# PIC18LF252 register map
Vendor: Microchip
Architecture 18xxxx. Special function registers and configuration words.
Registers are 8-bit, read-write, no defined reset value unless marked. A register's access mark holds for its fields unless they carry their own. Addresses are absolute, and some are shared; only a register's first bit layout is shown; lines under a group give offsets from that group; [hi:lo] are bit positions; {n}, {i} and the like mark numbered series; 'fields as' and 'values as' point back to an identical list; <NAME> marks a mode.

## Further device data
pins=1: MCLR/VPP; 2: RA0/AN0; 3: RA1/AN1; 4: RA2/AN2/VREF-; 5: RA3/AN3/VREF+; 6: RA4/T0CKI; 7: RA5/AN4/SS/LVDIN; 8: VSS; 9: OSC1/CLKI; 10: OSC2/CLKO/RA6; 11: RC0/T1OSO/T1CKI; 12: RC1/T1OSI/CCP2; 13: RC2/CCP1; 14: RC3/SCK/SCL; 15: RC4/SDI/SDA; 16: RC5/SDO; 17: RC6/TX/CK; 18: RC7/RX/DT; 19: VSS; 20: VDD; 21: RB0/INT0; 22: RB1/INT1; 23: RB2/INT2; 24: RB3/CCP2; 25: RB4; 26: RB5/PGM; 27: RB6/PGC; 28: RB7/PGD

## SFR
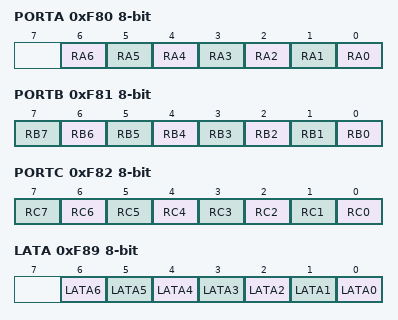
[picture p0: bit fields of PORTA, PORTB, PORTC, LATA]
0xF80 PORTA — (power-on value -x0x0000)
  [n] RA{n} (n=0..6)
0xF81 PORTB — (power-on value xxxxxxxx)
  [n] RB{n} (n=0..7)
0xF82 PORTC — (power-on value xxxxxxxx)
  [n] RC{n} (n=0..7)
0xF89 LATA — (power-on value -xxxxxxx)
  [n] LATA{n} (n=0..6)
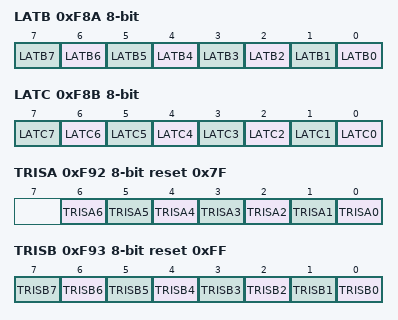
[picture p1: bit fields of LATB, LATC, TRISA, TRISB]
0xF8A LATB — (power-on value xxxxxxxx)
  [n] LATB{n} (n=0..7)
0xF8B LATC — (power-on value xxxxxxxx)
  [n] LATC{n} (n=0..7)
0xF92 TRISA reset 0x7F
  [n] TRISA{n} (n=0..6)
0xF93 TRISB reset 0xFF
  [n] TRISB{n} (n=0..7)
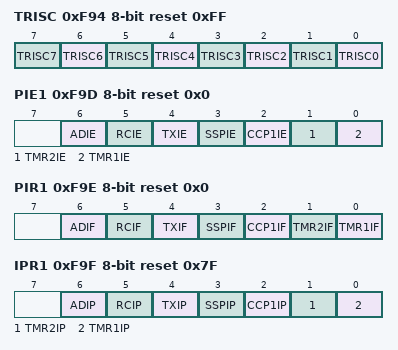
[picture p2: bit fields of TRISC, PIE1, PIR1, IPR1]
0xF94 TRISC reset 0xFF
  [n] TRISC{n} (n=0..7)
0xF9D PIE1 reset 0x0
  [6] ADIE, [5] RCIE, [4] TXIE, [3] SSPIE, [2] CCP1IE, [1] TMR2IE, [0] TMR1IE
0xF9E PIR1 reset 0x0
  [6] ADIF, [5] RCIF ro, [4] TXIF ro, [3] SSPIF, [2] CCP1IF, [1] TMR2IF, [0] TMR1IF
0xF9F IPR1 reset 0x7F
  [6] ADIP, [5] RCIP, [4] TXIP, [3] SSPIP, [2] CCP1IP, [1] TMR2IP, [0] TMR1IP
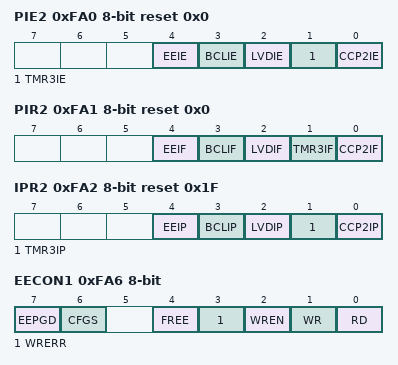
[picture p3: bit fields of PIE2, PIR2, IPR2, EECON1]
0xFA0 PIE2 reset 0x0
  [4] EEIE, [3] BCLIE, [2] LVDIE, [1] TMR3IE, [0] CCP2IE
0xFA1 PIR2 reset 0x0
  [4] EEIF, [3] BCLIF, [2] LVDIF, [1] TMR3IF, [0] CCP2IF
0xFA2 IPR2 reset 0x1F
  [4] EEIP, [3] BCLIP, [2] LVDIP, [1] TMR3IP, [0] CCP2IP
0xFA6 EECON1 — (power-on value xx-0x000)
  [7] EEPGD
  [6] CFGS
  [4] FREE
  [3] WRERR
  [2] WREN
  [1] WR — (can only be set)
  [0] RD — (can only be set)
0xFA7 EECON2 wo
0xFA8 EEDATA reset 0x0
0xFA9 EEADR reset 0x0
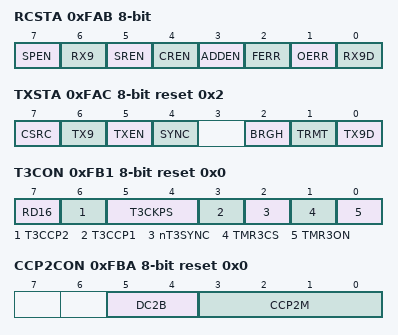
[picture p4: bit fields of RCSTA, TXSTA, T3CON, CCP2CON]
0xFAB RCSTA — (power-on value 0000000x)
  [7] SPEN, [6] RX9, [5] SREN, [4] CREN, [3] ADDEN, [2] FERR ro, [1] OERR ro, [0] RX9D ro
0xFAC TXSTA reset 0x2
  [7] CSRC, [6] TX9, [5] TXEN, [4] SYNC, [2] BRGH, [1] TRMT ro, [0] TX9D
0xFAD TXREG wo reset 0x0
0xFAE RCREG ro reset 0x0
0xFAF SPBRG reset 0x0
0xFB1 T3CON reset 0x0
  [7] RD16, [6] T3CCP2, [5:4] T3CKPS, [3] T3CCP1, [2] nT3SYNC, [1] TMR3CS, [0] TMR3ON
0xFB2 TMR3L — (power-on value xxxxxxxx)
0xFB3 TMR3H — (power-on value xxxxxxxx)
0xFBA CCP2CON reset 0x0
  [5:4] DC2B, [3:0] CCP2M
0xFBB CCPR2L — (power-on value xxxxxxxx)
0xFBC CCPR2H — (power-on value xxxxxxxx)
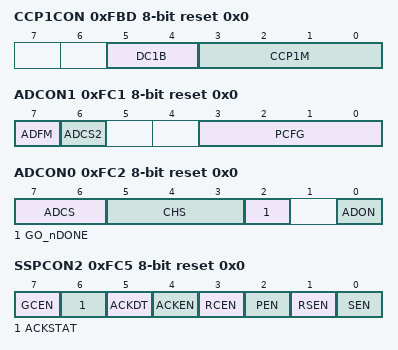
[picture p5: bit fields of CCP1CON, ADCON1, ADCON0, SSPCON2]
0xFBD CCP1CON reset 0x0
  [5:4] DC1B, [3:0] CCP1M
0xFBE CCPR1L — (power-on value xxxxxxxx)
0xFBF CCPR1H — (power-on value xxxxxxxx)
0xFC1 ADCON1 reset 0x0
  [7] ADFM, [6] ADCS2, [3:0] PCFG
0xFC2 ADCON0 reset 0x0
  [7:6] ADCS, [5:3] CHS, [2] GO_nDONE, [0] ADON
0xFC3 ADRESL — (power-on value xxxxxxxx)
0xFC4 ADRESH — (power-on value xxxxxxxx)
0xFC5 SSPCON2 reset 0x0
  [7] GCEN, [6] ACKSTAT, [5] ACKDT, [4] ACKEN, [3] RCEN, [2] PEN, [1] RSEN, [0] SEN
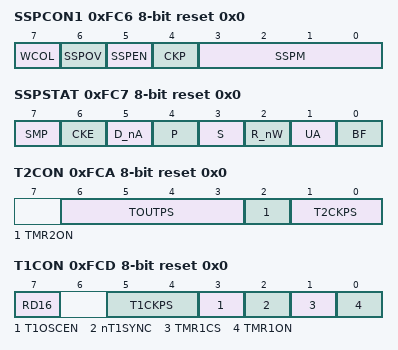
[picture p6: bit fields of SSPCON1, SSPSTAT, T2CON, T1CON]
0xFC6 SSPCON1 reset 0x0
  [7] WCOL, [6] SSPOV, [5] SSPEN, [4] CKP, [3:0] SSPM
0xFC7 SSPSTAT reset 0x0
  [7] SMP, [6] CKE, [5] D_nA, [4] P, [3] S, [2] R_nW, [1] UA, [0] BF
0xFC8 SSPADD reset 0x0
0xFC9 SSPBUF — (power-on value xxxxxxxx)
0xFCA T2CON reset 0x0
  [6:3] TOUTPS, [2] TMR2ON, [1:0] T2CKPS
0xFCB PR2 reset 0xFF
0xFCC TMR2 reset 0x0
0xFCD T1CON reset 0x0
  [7] RD16, [5:4] T1CKPS, [3] T1OSCEN, [2] nT1SYNC, [1] TMR1CS, [0] TMR1ON
0xFCE TMR1L — (power-on value xxxxxxxx)
0xFCF TMR1H — (power-on value xxxxxxxx)
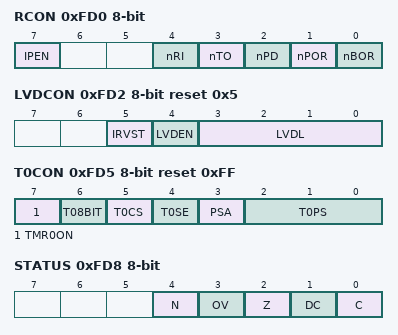
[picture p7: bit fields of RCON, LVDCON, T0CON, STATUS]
0xFD0 RCON — (power-on value 0--q1100)
  [7] IPEN, [4] nRI, [3] nTO, [2] nPD, [1] nPOR, [0] nBOR
0xFD1 WDTCON reset 0x0
  [0] SWDTEN
0xFD2 LVDCON reset 0x5
  [5] IRVST, [4] LVDEN, [3:0] LVDL
0xFD3 OSCCON reset 0x0
  [0] SCS
0xFD5 T0CON reset 0xFF
  [7] TMR0ON, [6] T08BIT, [5] T0CS, [4] T0SE, [3] PSA, [2:0] T0PS
0xFD6 TMR0L — (power-on value xxxxxxxx)
0xFD7 TMR0H reset 0x0
0xFD8 STATUS — (power-on value ---xxxxx)
  [4] N, [3] OV, [2] Z, [1] DC, [0] C
0xFD9 FSR2L — (power-on value xxxxxxxx)
0xFDA FSR2H reset 0x0
  [3:0] FSR2H
0xFDB PLUSW2 access not given
0xFDC PREINC2 access not given
0xFDD POSTDEC2 access not given
0xFDE POSTINC2 access not given
0xFDF INDF2 access not given
0xFE0 BSR reset 0x0
  [3:0] BSR
0xFE1 FSR1L — (power-on value xxxxxxxx)
0xFE2 FSR1H reset 0x0
  [3:0] FSR1H
0xFE3 PLUSW1 access not given
0xFE4 PREINC1 access not given
0xFE5 POSTDEC1 access not given
0xFE6 POSTINC1 access not given
0xFE7 INDF1 access not given
0xFE8 WREG — (power-on value xxxxxxxx)
0xFE9 FSR0L — (power-on value xxxxxxxx)
0xFEA FSR0H reset 0x0
  [3:0] FSR0H
0xFEB PLUSW0 access not given
0xFEC PREINC0 access not given
0xFED POSTDEC0 access not given
0xFEE POSTINC0 access not given
0xFEF INDF0 access not given
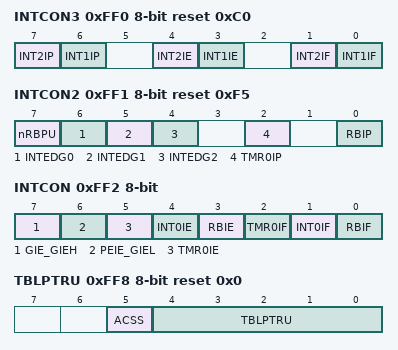
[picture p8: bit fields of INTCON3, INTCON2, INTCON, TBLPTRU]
0xFF0 INTCON3 reset 0xC0
  [7] INT2IP, [6] INT1IP, [4] INT2IE, [3] INT1IE, [1] INT2IF, [0] INT1IF
0xFF1 INTCON2 reset 0xF5
  [7] nRBPU, [6] INTEDG0, [5] INTEDG1, [4] INTEDG2, [2] TMR0IP, [0] RBIP
0xFF2 INTCON — (power-on value 0000000x)
  [7] GIE_GIEH, [6] PEIE_GIEL, [5] TMR0IE, [4] INT0IE, [3] RBIE, [2] TMR0IF, [1] INT0IF, [0] RBIF
0xFF3 PRODL — (power-on value xxxxxxxx)
0xFF4 PRODH — (power-on value xxxxxxxx)
0xFF5 TABLAT reset 0x0
0xFF6 TBLPTRL reset 0x0
0xFF7 TBLPTRH reset 0x0
0xFF8 TBLPTRU reset 0x0
  [5] ACSS, [4:0] TBLPTRU
0xFF9 PCL reset 0x0
0xFFA PCLATH reset 0x0
  [7:0] PCH
0xFFB PCLATU reset 0x0
  [4:0] PCU
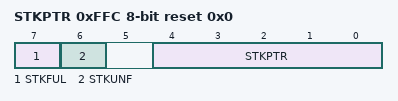
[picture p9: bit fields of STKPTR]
0xFFC STKPTR reset 0x0
  [7] STKFUL — (can only be cleared)
  [6] STKUNF — (can only be cleared)
  [4:0] STKPTR
0xFFD TOSL reset 0x0
0xFFE TOSH reset 0x0
0xFFF TOSU reset 0x0
  [4:0] TOSU
